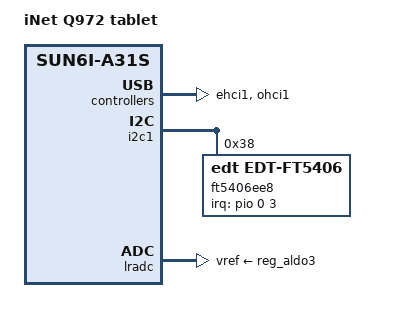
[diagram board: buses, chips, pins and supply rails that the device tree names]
/dts-v1/;
#include "sun6i-a31s.dtsi"
#include "sun6i-reference-design-tablet.dtsi"
/ {
	model = "iNet Q972 tablet";
	compatible = "inet-tek,inet-q972", "allwinner,sun6i-a31s";
};
&ehci1 {
	status = "okay";
};
&i2c1 {
	status = "okay";
	ft5406ee8: touchscreen@38 {
		compatible = "edt,edt-ft5406";
		reg = <0x38>;
		interrupt-parent = <&pio>;
		interrupts = <0 3 IRQ_TYPE_LEVEL_HIGH>;  
		touchscreen-size-x = <768>;
		touchscreen-size-y = <1024>;
		touchscreen-swapped-x-y;
	};
};
&lradc {
	vref-supply = <&reg_aldo3>;
	status = "okay";
	button-200 {
		label = "Volume Down";
		linux,code = <KEY_VOLUMEDOWN>;
		channel = <0>;
		voltage = <200000>;
	};
	button-900 {
		label = "Volume Up";
		linux,code = <KEY_VOLUMEUP>;
		channel = <0>;
		voltage = <900000>;
	};
	button-1200 {
		label = "Back";
		linux,code = <KEY_BACK>;
		channel = <0>;
		voltage = <1200000>;
	};
};
&ohci1 {
	status = "okay";
};
